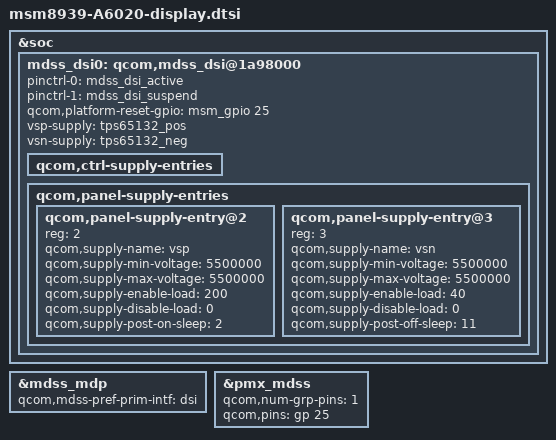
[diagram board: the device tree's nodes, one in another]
/* Copyright (c) 2014-2016, The Linux Foundation. All rights reserved.
 *
 * This program is free software; you can redistribute it and/or modify
 * it under the terms of the GNU General Public License version 2 and
 * only version 2 as published by the Free Software Foundation.
 *
 * This program is distributed in the hope that it will be useful,
 * but WITHOUT ANY WARRANTY; without even the implied warranty of
 * MERCHANTABILITY or FITNESS FOR A PARTICULAR PURPOSE.  See the
 * GNU General Public License for more details.
 */

&soc {
	mdss_dsi0: qcom,mdss_dsi@1a98000 {

		qcom,ctrl-supply-entries {
                        qcom,ctrl-supply-entry@0 {
                        /delete-property/ qcom,supply-post-on-sleep;
                        };
                };
        };
};     

&mdss_mdp {
	qcom,mdss-pref-prim-intf = "dsi";
};

&pmx_mdss {
	qcom,num-grp-pins = <1>;
	qcom,pins = <&gp 25>;
};

&mdss_dsi0 {
	pinctrl-names = "mdss_default", "mdss_sleep";
	pinctrl-0 = <&mdss_dsi_active>;
	pinctrl-1 = <&mdss_dsi_suspend>;
	qcom,platform-reset-gpio = <&msm_gpio 25 0>;
	//qcom,platform-bklight-en-gpio = <&msm_gpio 1 0>;
	vsp-supply = <&tps65132_pos>;
	vsn-supply = <&tps65132_neg>;

	qcom,ctrl-supply-entries {
		/delete-node/ qcom,ctrl-supply-entry@0;
	};

	qcom,panel-supply-entries {
		#address-cells = <1>;
		#size-cells = <0>;
		
		qcom,panel-supply-entry@2 {
			reg = <2>;
			qcom,supply-name = "vsp";
			qcom,supply-min-voltage = <5500000>;
			qcom,supply-max-voltage = <5500000>;
			qcom,supply-enable-load = <200>;
			qcom,supply-disable-load = <0>;
			qcom,supply-post-on-sleep = <2>;

		};

		qcom,panel-supply-entry@3 {
			reg = <3>;
			qcom,supply-name = "vsn";
			qcom,supply-min-voltage = <5500000>;
			qcom,supply-max-voltage = <5500000>;
			qcom,supply-enable-load = <40>;
			qcom,supply-disable-load = <0>;
			qcom,supply-post-off-sleep = <11>;
		};
	};
};
